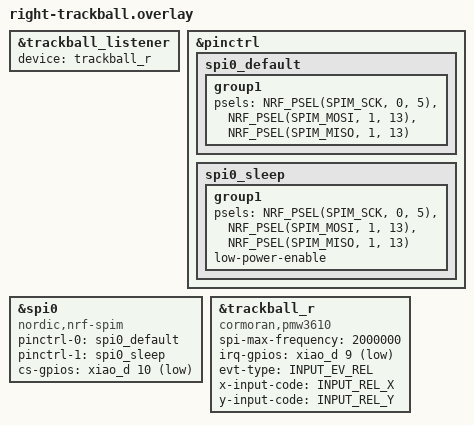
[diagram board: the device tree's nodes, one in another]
#include <zephyr/dt-bindings/input/input-event-codes.h>
#include <input/processors.dtsi>

&trackball_listener {
	status = "okay";
	device = <&trackball_r>;
};

&pinctrl {
	spi0_default: spi0_default {
		group1 {
			psels = <NRF_PSEL(SPIM_SCK, 0, 5)>,// D5
			<NRF_PSEL(SPIM_MOSI, 1, 13)>,// D8
			<NRF_PSEL(SPIM_MISO, 1, 13)>;// D8
		};
	};
	
	spi0_sleep: spi0_sleep {
		group1 {
			psels = <NRF_PSEL(SPIM_SCK, 0, 5)>,
			<NRF_PSEL(SPIM_MOSI, 1, 13)>,
			<NRF_PSEL(SPIM_MISO, 1, 13)>;
			low-power-enable;
		};
	};
};

&spi0 {
	compatible = "nordic,nrf-spim";
	status = "okay";
	pinctrl-0 = <&spi0_default>;
	pinctrl-1 = <&spi0_sleep>;
	pinctrl-names = "default", "sleep";
	cs-gpios = <&xiao_d 10 GPIO_ACTIVE_LOW>;
};

&trackball_r {
	status = "okay";
	compatible = "cormoran,pmw3610";
	// 2MHz suggested in datasheet
	spi-max-frequency = <2000000>;
	irq-gpios = <&xiao_d 9 (GPIO_ACTIVE_LOW | GPIO_PULL_UP)>;
	evt-type = <INPUT_EV_REL>;
	x-input-code = <INPUT_REL_X>;
	y-input-code = <INPUT_REL_Y>;
	// disable force-awake
	// force-awake;
	// disable-burst-read;
};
